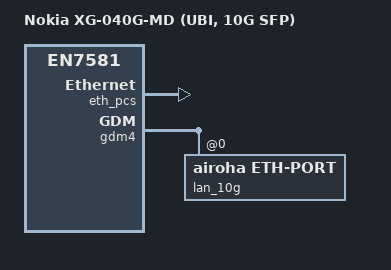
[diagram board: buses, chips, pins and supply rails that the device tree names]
// SPDX-License-Identifier: GPL-2.0-only OR MIT

#include "an7581-nokia_xg-040g-md-common.dtsi"
#include "an758x-nokia_xg-040g-ubi-parts.dtsi"

/ {
	model = "Nokia XG-040G-MD (UBI, 10G SFP)";
	compatible = "nokia,xg-040g-md-ubi", "airoha,an7581",
		     "airoha,en7581";
	variant = "10g-sfp";
};

/* The EN8811H 2.5G PHY is not populated on this variant. */
&mdio {
	/delete-node/ ethernet-phy@f;
};

&eth_pcs {
	status = "okay";
};

&gdm4 {
	/delete-property/ pcs-handle;
	/delete-property/ phy-handle;
	/delete-property/ phy-mode;

	#address-cells = <1>;
	#size-cells = <0>;
	status = "okay";

	/*
	 * 10G SFP cage wired directly to the Ethernet SerDes (NBQ0).
	 *
	 * No SFP EEPROM I2C is available: the SoC MDIO pins (GPIO1/GPIO2)
	 * are hard-connected to the internal switch MDIO bus and cannot be
	 * reused as a bit-banged I2C bus, and no other I2C master reaches
	 * the cage. The link is therefore brought up by the PCS using
	 * in-band status at a fixed 10GBASE-R rate. Only modules that
	 * present a 10GBASE-R (or compatible) SerDes signal will link
	 * (10G AOC/DAC/optics, 10GBASE-T copper modules); 1G/2.5G copper
	 * SFP modules that drive SGMII/2500BASE-X are not supported.
	 */
	lan_10g: ethernet-port@0 {
		compatible = "airoha,eth-port";
		reg = <0>;
		managed = "in-band-status";
		pcs-handle = <&eth_pcs>;
		phy-mode = "10gbase-r";
		nvmem-cell-names = "mac-address";
		nvmem-cells = <&macaddr_factory_3e 0>;
		openwrt,netdev-name = "lan1";
		status = "okay";
	};
};
